# STM32WL5x_CM0P register map
File version: 1.5
CPU: CM0 r0p1, little endian, MPU, no FPU, 4 interrupt priority bits
Registers are 32-bit, read-write, reset 0x0 unless marked. A register's access mark holds for its fields unless they carry their own. Offsets are from the block's base; [hi:lo] are bit positions.

## RCC — Reset and clock control
Base 0x58000000
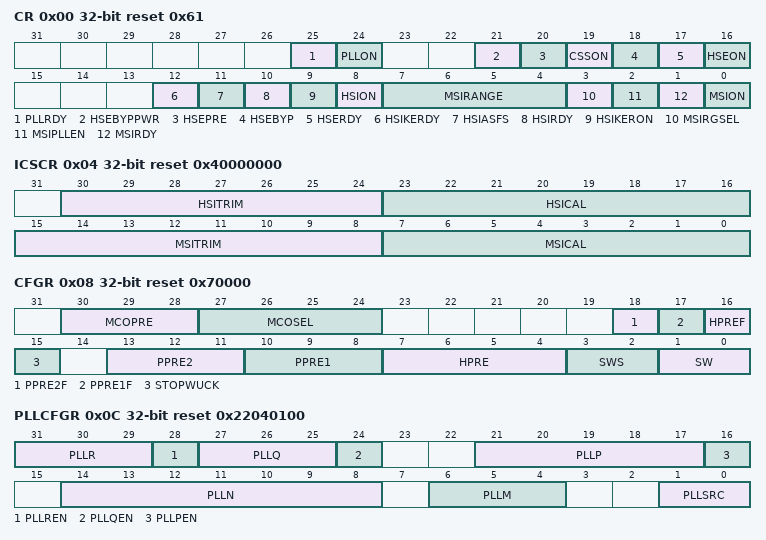
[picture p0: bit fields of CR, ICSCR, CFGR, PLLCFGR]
0x00 CR access per field reset 0x61 — Clock control register
  [25] PLLRDY ro — Main PLL clock ready flag
  [24] PLLON rw — Main PLL enable
  [21] HSEBYPPWR rw — Enable HSE32 VDDTCXO output on package pin PB0-VDDTCXO.
  [20] HSEPRE rw — HSE32 sysclk prescaler
  [19] CSSON wo — HSE32 Clock security system enable
  [18] HSEBYP rw — HSE32 crystal oscillator bypass
  [17] HSERDY ro — HSE32 clock ready flag
  [16] HSEON rw — HSE32 clock enable
  [12] HSIKERDY ro — HSI16 kernel clock ready flag for peripherals requests.
  [11] HSIASFS rw — HSI16 automatic start from Stop
  [10] HSIRDY ro — HSI16 clock ready flag. (After wakeup from Stop this bit will be read 1 once the HSI16 is ready)
  [9] HSIKERON rw — HSI16 always enable for peripheral kernel clocks.
  [8] HSION rw — HSI16 clock enable
  [7:4] MSIRANGE rw — MSI clock ranges
  [3] MSIRGSEL wo — MSI range control selection
  [2] MSIPLLEN rw — MSI clock PLL enable
  [1] MSIRDY ro — MSI clock ready flag (After reset this bit will be read 1 once the MSI is ready)
  [0] MSION rw — MSI clock enable
0x04 ICSCR access per field reset 0x40000000 — Internal clock sources calibration register
  [30:24] HSITRIM rw — HSI16 clock trimming
  [23:16] HSICAL ro — HSI16 clock calibration
  [15:8] MSITRIM rw — MSI clock trimming
  [7:0] MSICAL ro — MSI clock calibration
0x08 CFGR access per field reset 0x70000 — Clock configuration register
  [30:28] MCOPRE rw — Microcontroller clock output prescaler
  [27:24] MCOSEL rw — Microcontroller clock output
  [18] PPRE2F ro — PCLK2 prescaler flag (APB2)
  [17] PPRE1F ro — PCLK1 prescaler flag (APB1)
  [16] HPREF ro — HCLK1 prescaler flag (CPU1, AHB1, AHB2, and SRAM1)
  [15] STOPWUCK rw — Wakeup from Stop and CSS backup clock selection
  [13:11] PPRE2 rw — PCLK2 high-speed prescaler (APB2)
  [10:8] PPRE1 rw — PCLK1 low-speed prescaler (APB1)
  [7:4] HPRE rw — HCLK1 prescaler (CPU1, AHB1, AHB2, and SRAM1.)
  [3:2] SWS ro — System clock switch status
  [1:0] SW rw — System clock switch
0x0C PLLCFGR reset 0x22040100 — PLL configuration register
  [31:29] PLLR — Main PLL division factor for PLLRCLK
  [28] PLLREN — Main PLL PLLRCLK output enable
  [27:25] PLLQ — Main PLL division factor for PLLQCLK
  [24] PLLQEN — Main PLL PLLQCLK output enable
  [21:17] PLLP — Main PLL division factor for PLLPCLK.
  [16] PLLPEN — Main PLL PLLPCLK output enable
  [14:8] PLLN — Main PLL multiplication factor for VCO
  [6:4] PLLM — Division factor for the main PLL input clock
  [1:0] PLLSRC — Main PLL entry clock source
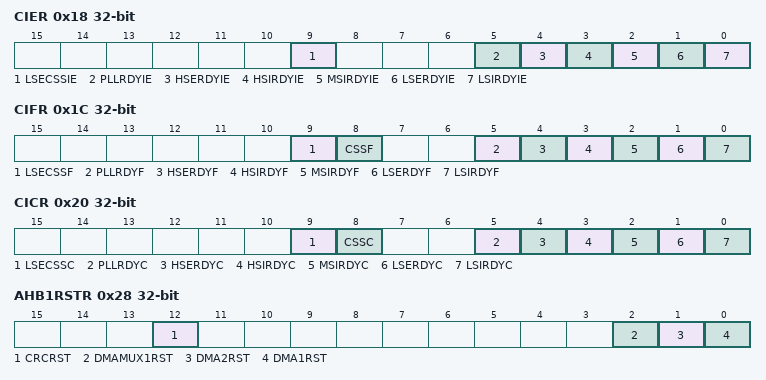
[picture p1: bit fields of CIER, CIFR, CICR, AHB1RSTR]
0x18 CIER — Clock interrupt enable register
  [9] LSECSSIE — LSE clock security system interrupt enable
  [5] PLLRDYIE — PLL ready interrupt enable
  [4] HSERDYIE — HSE32 ready interrupt enable
  [3] HSIRDYIE — HSI16 ready interrupt enable
  [2] MSIRDYIE — MSI ready interrupt enable
  [1] LSERDYIE — LSE ready interrupt enable
  [0] LSIRDYIE — LSI ready interrupt enable
0x1C CIFR ro — Clock interrupt flag register
  [9] LSECSSF — LSE Clock security system interrupt flag
  [8] CSSF — HSE32 Clock security system interrupt flag
  [5] PLLRDYF — PLL ready interrupt flag
  [4] HSERDYF — HSE32 ready interrupt flag
  [3] HSIRDYF — HSI16 ready interrupt flag
  [2] MSIRDYF — MSI ready interrupt flag
  [1] LSERDYF — LSE ready interrupt flag
  [0] LSIRDYF — LSI ready interrupt flag
0x20 CICR wo — Clock interrupt clear register
  [9] LSECSSC — LSE Clock security system interrupt clear
  [8] CSSC — HSE32 Clock security system interrupt clear
  [5] PLLRDYC — PLL ready interrupt clear
  [4] HSERDYC — HSE32 ready interrupt clear
  [3] HSIRDYC — HSI16 ready interrupt clear
  [2] MSIRDYC — MSI ready interrupt clear
  [1] LSERDYC — LSE ready interrupt clear
  [0] LSIRDYC — LSI ready interrupt clear
0x28 AHB1RSTR — AHB1 peripheral reset register
  [12] CRCRST — CRC reset
  [2] DMAMUX1RST — DMAMUX1 reset
  [1] DMA2RST — DMA2 reset
  [0] DMA1RST — DMA1 reset
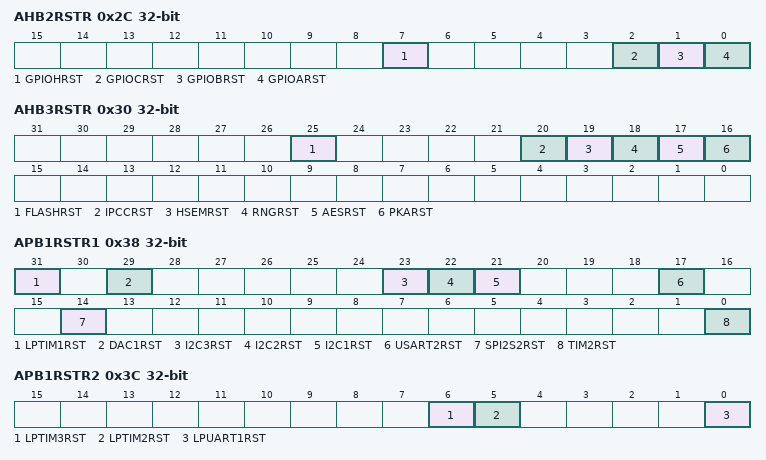
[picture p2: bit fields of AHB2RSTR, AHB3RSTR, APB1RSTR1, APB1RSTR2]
0x2C AHB2RSTR — AHB2 peripheral reset register
  [7] GPIOHRST — IO port H reset
  [2] GPIOCRST — IO port C reset
  [1] GPIOBRST — IO port B reset
  [0] GPIOARST — IO port A reset
0x30 AHB3RSTR — AHB3 peripheral reset register
  [25] FLASHRST — Flash interface reset
  [20] IPCCRST
  [19] HSEMRST
  [18] RNGRST
  [17] AESRST
  [16] PKARST
0x38 APB1RSTR1 — APB1 peripheral reset register 1
  [31] LPTIM1RST — Low Power Timer 1 reset
  [29] DAC1RST — DAC1 reset
  [23] I2C3RST — I2C3 reset
  [22] I2C2RST — I2C2 reset
  [21] I2C1RST — I2C1 reset
  [17] USART2RST — USART2 reset
  [14] SPI2S2RST — SPI2S2 reset
  [0] TIM2RST — TIM2 timer reset
0x3C APB1RSTR2 — APB1 peripheral reset register 2
  [6] LPTIM3RST — Low-power timer 3 reset
  [5] LPTIM2RST — Low-power timer 2 reset
  [0] LPUART1RST — Low-power UART 1 reset
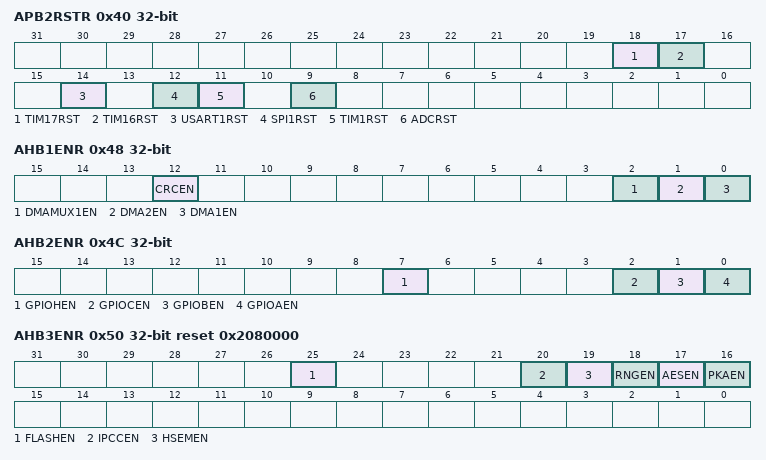
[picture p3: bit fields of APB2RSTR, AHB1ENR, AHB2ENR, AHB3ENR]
0x40 APB2RSTR — APB2 peripheral reset register
  [18] TIM17RST — TIM17 timer reset
  [17] TIM16RST — TIM16 timer reset
  [14] USART1RST — USART1 reset
  [12] SPI1RST — SPI1 reset
  [11] TIM1RST — TIM1 timer reset
  [9] ADCRST — ADC reset
0x44 APB3RSTR — APB3 peripheral reset register
  [0] SPI3RST — SPI3 reset
0x48 AHB1ENR — AHB1 peripheral clock enable register
  [12] CRCEN — CPU1 CRC clock enable
  [2] DMAMUX1EN — CPU1 DMAMUX1 clock enable
  [1] DMA2EN — CPU1 DMA2 clock enable
  [0] DMA1EN — CPU1 DMA1 clock enable
0x4C AHB2ENR — AHB2 peripheral clock enable register
  [7] GPIOHEN — CPU1 IO port H clock enable
  [2] GPIOCEN — CPU1 IO port C clock enable
  [1] GPIOBEN — CPU1 IO port B clock enable
  [0] GPIOAEN — CPU1 IO port A clock enable
0x50 AHB3ENR reset 0x2080000 — AHB3 peripheral clock enable register
  [25] FLASHEN — CPU1 Flash interface clock enable
  [20] IPCCEN
  [19] HSEMEN
  [18] RNGEN
  [17] AESEN
  [16] PKAEN
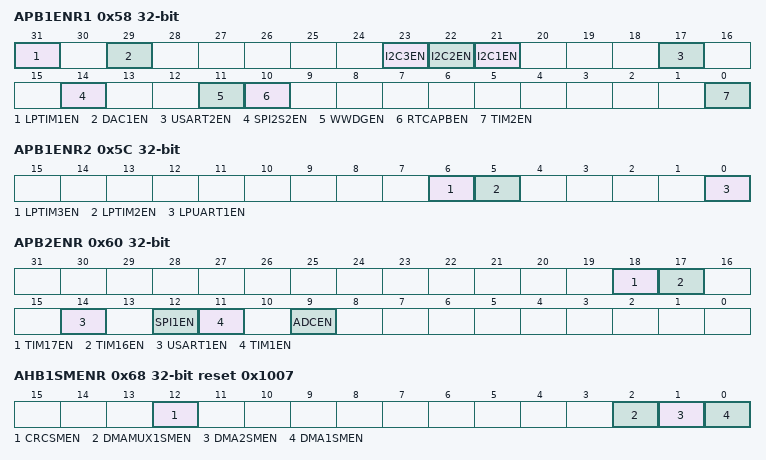
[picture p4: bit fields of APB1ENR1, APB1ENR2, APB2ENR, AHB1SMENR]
0x58 APB1ENR1 access per field — APB1 peripheral clock enable register 1
  [31] LPTIM1EN rw — CPU1 Low power timer 1 clocks enable
  [29] DAC1EN rw — CPU1 DAC1 clock enable
  [23] I2C3EN rw — CPU1 I2C3 clocks enable
  [22] I2C2EN rw — CPU1 I2C2 clocks enable
  [21] I2C1EN rw — CPU1 I2C1 clocks enable
  [17] USART2EN rw — CPU1 USART2 clock enable
  [14] SPI2S2EN rw — CPU1 SPI2S2 clock enable
  [11] WWDGEN wo — CPU1 Window watchdog clock enable
  [10] RTCAPBEN rw — CPU1 RTC APB clock enable
  [0] TIM2EN rw — CPU1 TIM2 timer clock enable
0x5C APB1ENR2 — APB1 peripheral clock enable register 2
  [6] LPTIM3EN — CPU1 Low power timer 3 clocks enable
  [5] LPTIM2EN — CPU1 Low power timer 2 clocks enable
  [0] LPUART1EN — CPU1 Low power UART 1 clocks enable
0x60 APB2ENR — APB2 peripheral clock enable register
  [18] TIM17EN — CPU1 TIM17 timer clock enable
  [17] TIM16EN — CPU1 TIM16 timer clock enable
  [14] USART1EN — CPU1 USART1clocks enable
  [12] SPI1EN — CPU1 SPI1 clock enable
  [11] TIM1EN — CPU1 TIM1 timer clock enable
  [9] ADCEN — CPU1 ADC clocks enable
0x64 APB3ENR — APB3 peripheral clock enable register
  [0] SPI3EN — CPU1 SPI3 clock enable
0x68 AHB1SMENR reset 0x1007 — AHB1 peripheral clocks enable in Sleep modes register
  [12] CRCSMEN — CRC clock enable during CPU1 CSleep mode.
  [2] DMAMUX1SMEN — DMAMUX1 clock enable during CPU1 CSleep mode.
  [1] DMA2SMEN — DMA2 clock enable during CPU1 CSleep mode
  [0] DMA1SMEN — DMA1 clock enable during CPU1 CSleep mode.
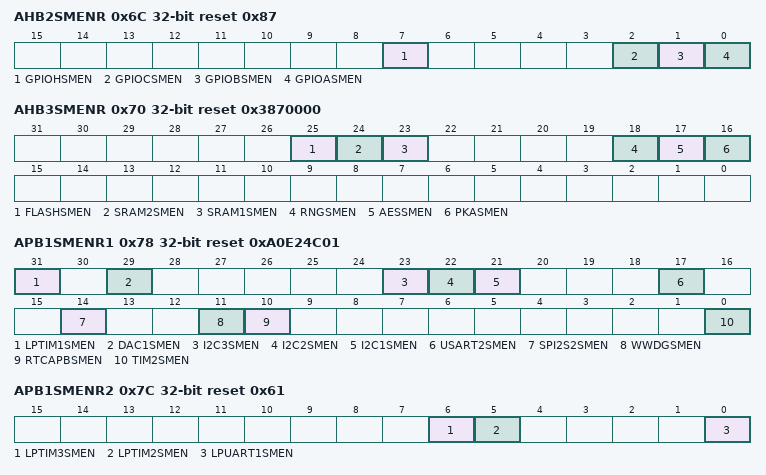
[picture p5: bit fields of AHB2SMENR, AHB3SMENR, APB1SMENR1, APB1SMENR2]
0x6C AHB2SMENR reset 0x87 — AHB2 peripheral clocks enable in Sleep modes register
  [7] GPIOHSMEN — IO port H clock enable during CPU1 CSleep mode.
  [2] GPIOCSMEN — IO port C clock enable during CPU1 CSleep mode.
  [1] GPIOBSMEN — IO port B clock enable during CPU1 CSleep mode.
  [0] GPIOASMEN — IO port A clock enable during CPU1 CSleep mode.
0x70 AHB3SMENR reset 0x3870000 — AHB3 peripheral clocks enable in Sleep and Stop modes register
  [25] FLASHSMEN — Flash interface clock enable during CPU1 CSleep mode.
  [24] SRAM2SMEN — SRAM2 memory interface clock enable during CPU1 CSleep mode
  [23] SRAM1SMEN — SRAM1 interface clock enable during CPU1 CSleep mode.
  [18] RNGSMEN — True RNG clocks enable during CPU1 Csleep and CStop modes
  [17] AESSMEN — AES accelerator clock enable during CPU1 CSleep mode.
  [16] PKASMEN — PKA accelerator clock enable during CPU1 CSleep mode.
0x78 APB1SMENR1 reset 0xA0E24C01 — APB1 peripheral clocks enable in Sleep mode register 1
  [31] LPTIM1SMEN — Low power timer 1 clock enable during CPU1 Csleep and CStop mode
  [29] DAC1SMEN — DAC1 clock enable during CPU1 CSleep mode.
  [23] I2C3SMEN — I2C3 clock enable during CPU1 Csleep and CStop modes
  [22] I2C2SMEN — I2C2 clock enable during CPU1 Csleep and CStop modes
  [21] I2C1SMEN — I2C1 clock enable during CPU1 Csleep and CStop modes
  [17] USART2SMEN — USART2 clock enable during CPU1 CSleep mode.
  [14] SPI2S2SMEN — SPI2S2 clock enable during CPU1 CSleep mode.
  [11] WWDGSMEN — Window watchdog clocks enable during CPU1 CSleep mode.
  [10] RTCAPBSMEN — RTC bus clock enable during CPU1 CSleep mode.
  [0] TIM2SMEN — TIM2 timer clock enable during CPU1 CSleep mode.
0x7C APB1SMENR2 reset 0x61 — APB1 peripheral clocks enable in Sleep mode register 2
  [6] LPTIM3SMEN — Low power timer 3 clock enable during CPU1 Csleep and CStop modes
  [5] LPTIM2SMEN — Low power timer 2 clock enable during CPU1 Csleep and CStop modes
  [0] LPUART1SMEN — Low power UART 1 clock enable during CPU1 Csleep and CStop modes.
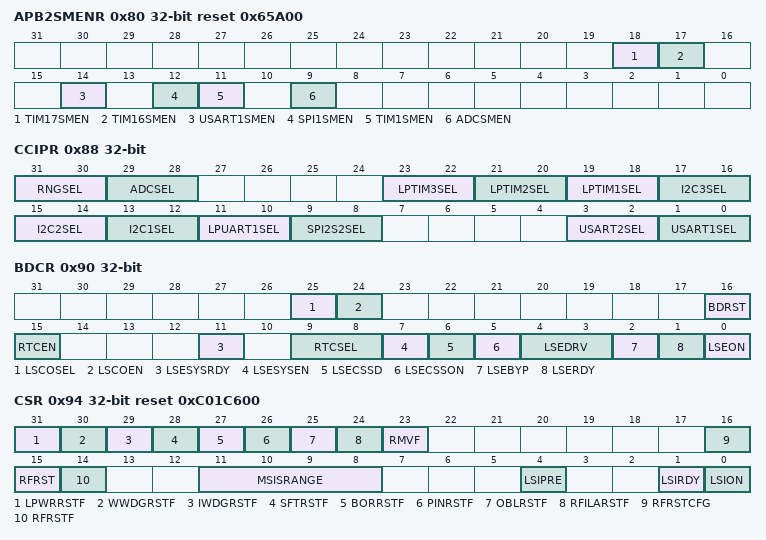
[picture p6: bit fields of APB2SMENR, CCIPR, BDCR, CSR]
0x80 APB2SMENR reset 0x65A00 — APB2 peripheral clocks enable in Sleep mode register
  [18] TIM17SMEN — TIM17 timer clock enable during CPU1 CSleep mode.
  [17] TIM16SMEN — TIM16 timer clock enable during CPU1 CSleep mode.
  [14] USART1SMEN — USART1 clock enable during CPU1 Csleep and CStop modes.
  [12] SPI1SMEN — SPI1 clock enable during CPU1 CSleep mode.
  [11] TIM1SMEN — TIM1 timer clock enable during CPU1 CSleep mode.
  [9] ADCSMEN — ADC clocks enable during CPU1 Csleep and CStop modes
0x84 APB3SMENR reset 0x1 — APB3 peripheral clock enable in Sleep mode register
  [0] SPI3SMEN — SPI3 clock enable during CPU1 CSleep mode.
0x88 CCIPR — Peripherals independent clock configuration register
  [31:30] RNGSEL — RNG clock source selection
  [29:28] ADCSEL — ADC clock source selection
  [23:22] LPTIM3SEL — Low power timer 3 clock source selection
  [21:20] LPTIM2SEL — Low power timer 2 clock source selection
  [19:18] LPTIM1SEL — Low power timer 1 clock source selection
  [17:16] I2C3SEL — I2C3 clock source selection
  [15:14] I2C2SEL — I2C2 clock source selection
  [13:12] I2C1SEL — I2C1 clock source selection
  [11:10] LPUART1SEL — LPUART1 clock source selection
  [9:8] SPI2S2SEL — SPI2S2 I2S clock source selection
  [3:2] USART2SEL — USART2 clock source selection
  [1:0] USART1SEL — USART1 clock source selection
0x90 BDCR access per field — Backup domain control register
  [25] LSCOSEL rw — Low speed clock output selection
  [24] LSCOEN rw — Low speed clock output enable
  [16] BDRST rw — Backup domain software reset
  [15] RTCEN rw — RTC clock enable
  [11] LSESYSRDY ro — LSE system clock ready
  [9:8] RTCSEL rw — RTC clock source selection
  [7] LSESYSEN rw — LSE system clock enable
  [6] LSECSSD ro — CSS on LSE failure Detection
  [5] LSECSSON rw — CSS on LSE enable
  [4:3] LSEDRV rw — LSE oscillator drive capability
  [2] LSEBYP rw — LSE oscillator bypass
  [1] LSERDY ro — LSE oscillator ready
  [0] LSEON rw — LSE oscillator enable
0x94 CSR access per field reset 0xC01C600 — Control/status register
  [31] LPWRRSTF ro — Low-power reset flag
  [30] WWDGRSTF ro — Window watchdog reset flag
  [29] IWDGRSTF ro — Independent window watchdog reset flag
  [28] SFTRSTF ro — Software reset flag
  [27] BORRSTF ro — BOR flag
  [26] PINRSTF ro — Pin reset flag
  [25] OBLRSTF ro — Option byte loader reset flag
  [24] RFILARSTF ro — Radio illegal access flag
  [23] RMVF rw — Remove reset flag
  [16] RFRSTCFG rw — Radio reset configuration (Non user)
  [15] RFRST rw — Radio reset
  [14] RFRSTF ro — Radio in reset status flag
  [11:8] MSISRANGE rw — MSI clock ranges
  [4] LSIPRE rw — LSI frequency prescaler
  [1] LSIRDY ro — LSI oscillator ready
  [0] LSION rw — LSI oscillator enable
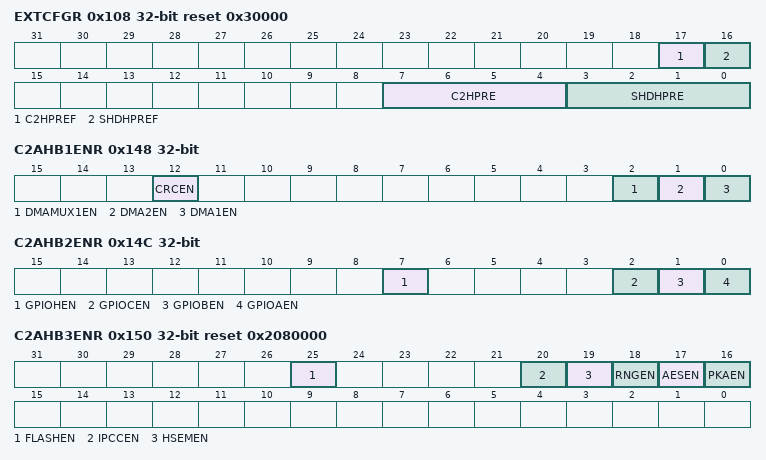
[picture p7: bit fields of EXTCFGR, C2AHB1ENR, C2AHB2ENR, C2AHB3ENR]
0x108 EXTCFGR access per field reset 0x30000 — Extended clock recovery register
  [17] C2HPREF ro — CLK2 prescaler flag (CPU2)
  [16] SHDHPREF ro — HCLK3 shared prescaler flag (AHB3, Flash, and SRAM2)
  [7:4] C2HPRE rw — [dual core device only] HCLK2 prescaler (CPU2)
  [3:0] SHDHPRE rw — HCLK3 shared prescaler (AHB3, Flash, and SRAM2)
0x148 C2AHB1ENR — CPU2 AHB1 peripheral clock enable register
  [12] CRCEN — CPU2 CRC clock enable
  [2] DMAMUX1EN — CPU2 DMAMUX1 clock enable
  [1] DMA2EN — CPU2 DMA2 clock enable
  [0] DMA1EN — CPU2 DMA1 clock enable
0x14C C2AHB2ENR — CPU2 AHB2 peripheral clock enable register
  [7] GPIOHEN — CPU2 IO port H clock enable
  [2] GPIOCEN — CPU2 IO port C clock enable
  [1] GPIOBEN — CPU2 IO port B clock enable
  [0] GPIOAEN — CPU2 IO port A clock enable
0x150 C2AHB3ENR reset 0x2080000 — CPU2 AHB3 peripheral clock enable register [dual core device only]
  [25] FLASHEN — CPU2 Flash interface clock enable
  [20] IPCCEN — CPU2 IPCC interface clock enable
  [19] HSEMEN — CPU2 HSEM clock enable
  [18] RNGEN — CPU2 True RNG clocks enable
  [17] AESEN — CPU2 AES accelerator clock enable
  [16] PKAEN — CPU2 PKA accelerator clock enable
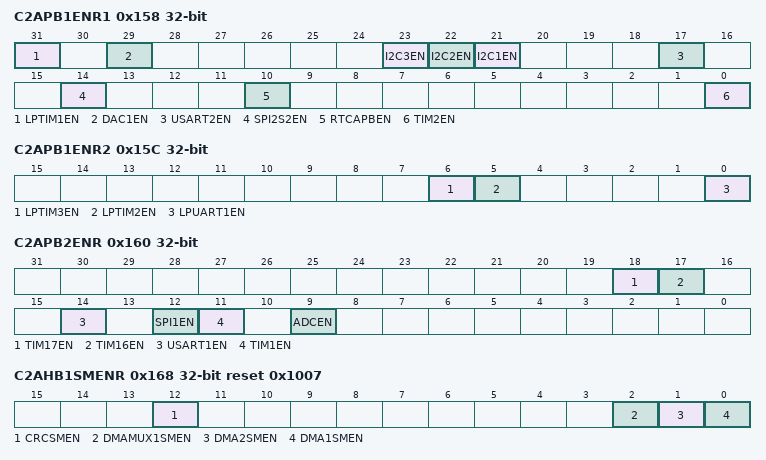
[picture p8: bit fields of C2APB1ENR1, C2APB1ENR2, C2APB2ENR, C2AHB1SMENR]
0x158 C2APB1ENR1 — CPU2 APB1 peripheral clock enable register 1 [dual core device only]
  [31] LPTIM1EN — CPU2 Low power timer 1 clocks enable
  [29] DAC1EN — CPU2 DAC1 clock enable
  [23] I2C3EN — CPU2 I2C3 clocks enable
  [22] I2C2EN — CPU2 I2C2 clocks enable
  [21] I2C1EN — CPU2 I2C1 clocks enable
  [17] USART2EN — CPU2 USART2 clock enable
  [14] SPI2S2EN — CPU2 SPI2S2 clock enable
  [10] RTCAPBEN — CPU2 RTC APB clock enable
  [0] TIM2EN — CPU2 TIM2 timer clock enable
0x15C C2APB1ENR2 — CPU2 APB1 peripheral clock enable register 2 [dual core device only]
  [6] LPTIM3EN — CPU2 Low power timer 3 clocks enable
  [5] LPTIM2EN — CPU2 Low power timer 2 clocks enable
  [0] LPUART1EN — CPU2 Low power UART 1 clocks enable
0x160 C2APB2ENR — CPU2 APB2 peripheral clock enable register [dual core device only]
  [18] TIM17EN — CPU2 TIM17 timer clock enable
  [17] TIM16EN — CPU2 TIM16 timer clock enable
  [14] USART1EN — CPU2 USART1clocks enable
  [12] SPI1EN — CPU2 SPI1 clock enable
  [11] TIM1EN — CPU2 TIM1 timer clock enable
  [9] ADCEN — ADC clocks enable
0x164 C2APB3ENR — CPU2 APB3 peripheral clock enable register [dual core device only]
  [0] SPI3EN — CPU2 SPI3 clock enable
0x168 C2AHB1SMENR reset 0x1007 — CPU2 AHB1 peripheral clocks enable in Sleep modes register [dual core device only]
  [12] CRCSMEN — CRC clock enable during CPU2 CSleep mode.
  [2] DMAMUX1SMEN — DMAMUX1 clock enable during CPU2 CSleep mode.
  [1] DMA2SMEN — DMA2 clock enable during CPU2 CSleep mode.
  [0] DMA1SMEN — DMA1 clock enable during CPU2 CSleep mode.
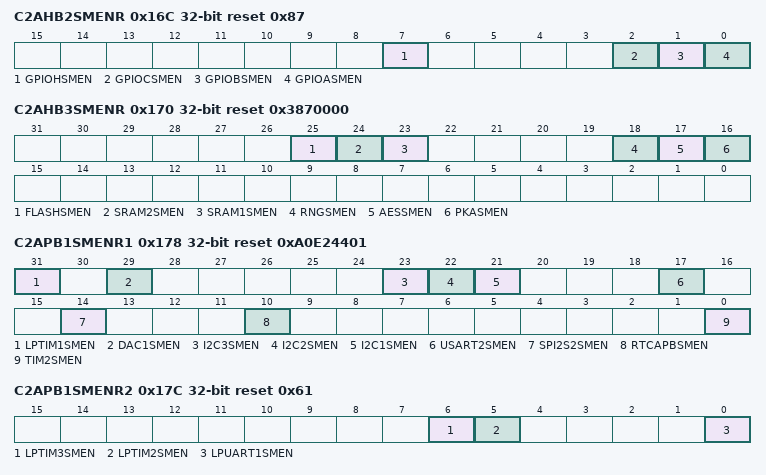
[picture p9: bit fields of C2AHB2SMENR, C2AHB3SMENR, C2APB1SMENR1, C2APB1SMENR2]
0x16C C2AHB2SMENR reset 0x87 — CPU2 AHB2 peripheral clocks enable in Sleep modes register [dual core device only]
  [7] GPIOHSMEN — IO port H clock enable during CPU2 CSleep mode.
  [2] GPIOCSMEN — IO port C clock enable during CPU2 CSleep mode.
  [1] GPIOBSMEN — IO port B clock enable during CPU2 CSleep mode.
  [0] GPIOASMEN — IO port A clock enable during CPU2 CSleep mode.
0x170 C2AHB3SMENR reset 0x3870000 — CPU2 AHB3 peripheral clocks enable in Sleep mode register [dual core device only]
  [25] FLASHSMEN — Flash interface clock enable during CPU2 CSleep mode.
  [24] SRAM2SMEN — SRAM2 memory interface clock enable during CPU2 CSleep mode.
  [23] SRAM1SMEN — SRAM1 interface clock enable during CPU2 CSleep mode.
  [18] RNGSMEN — True RNG clock enable during CPU2 CSleep and CStop mode.
  [17] AESSMEN — AES accelerator clock enable during CPU2 CSleep mode.
  [16] PKASMEN — PKA accelerator clock enable during CPU2 CSleep mode.
0x178 C2APB1SMENR1 reset 0xA0E24401 — CPU2 APB1 peripheral clocks enable in Sleep mode register 1 [dual core device only]
  [31] LPTIM1SMEN — Low power timer 1 clock enable during CPU2 CSleep and CStop mode
  [29] DAC1SMEN — DAC1 clock enable during CPU2 CSleep mode.
  [23] I2C3SMEN — I2C3 clock enable during CPU2 CSleep and CStop modes
  [22] I2C2SMEN — I2C2 clock enable during CPU2 CSleep and CStop modes
  [21] I2C1SMEN — I2C1 clock enable during CPU2 CSleep and CStop modes
  [17] USART2SMEN — USART2 clock enable during CPU2 CSleep mode.
  [14] SPI2S2SMEN — SPI2S2 clock enable during CPU2 CSleep mode.
  [10] RTCAPBSMEN — RTC bus clock enable during CPU2 CSleep mode.
  [0] TIM2SMEN — TIM2 timer clock enable during CPU2 CSleep mode.
0x17C C2APB1SMENR2 reset 0x61 — CPU2 APB1 peripheral clocks enable in Sleep mode register 2 [dual core device only]
  [6] LPTIM3SMEN — Low power timer 3 clocks enable during CPU2 CSleep and CStop modes.
  [5] LPTIM2SMEN — Low power timer 2 clocks enable during CPU2 CSleep and CStop modes.
  [0] LPUART1SMEN — Low power UART 1 clock enable during CPU2 CSleep and CStop mode
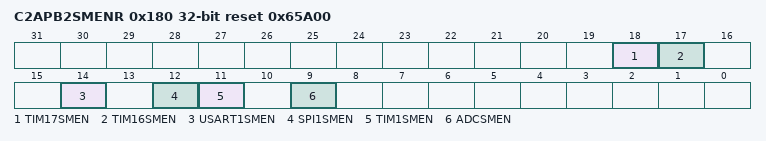
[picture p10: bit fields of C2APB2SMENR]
0x180 C2APB2SMENR reset 0x65A00 — CPU2 APB2 peripheral clocks enable in Sleep mode register [dual core device only]
  [18] TIM17SMEN — TIM17 timer clock enable during CPU2 CSleep mode
  [17] TIM16SMEN — TIM16 timer clock enable during CPU2 CSleep mode
  [14] USART1SMEN — USART1clock enable during CPU2 CSleep and CStop mode
  [12] SPI1SMEN — SPI1 clock enable during CPU2 CSleep mode
  [11] TIM1SMEN — TIM1 timer clock enable during CPU2 CSleep mode
  [9] ADCSMEN — ADC clocks enable during CPU2 Csleep and CStop modes
0x184 C2APB3SMENR reset 0x1 — CPU2 APB3 peripheral clock enable in Sleep mode register [dual core device only]
  [0] SPI3SMEN — SPI3 clock enable during CPU2 CSleep mode.
